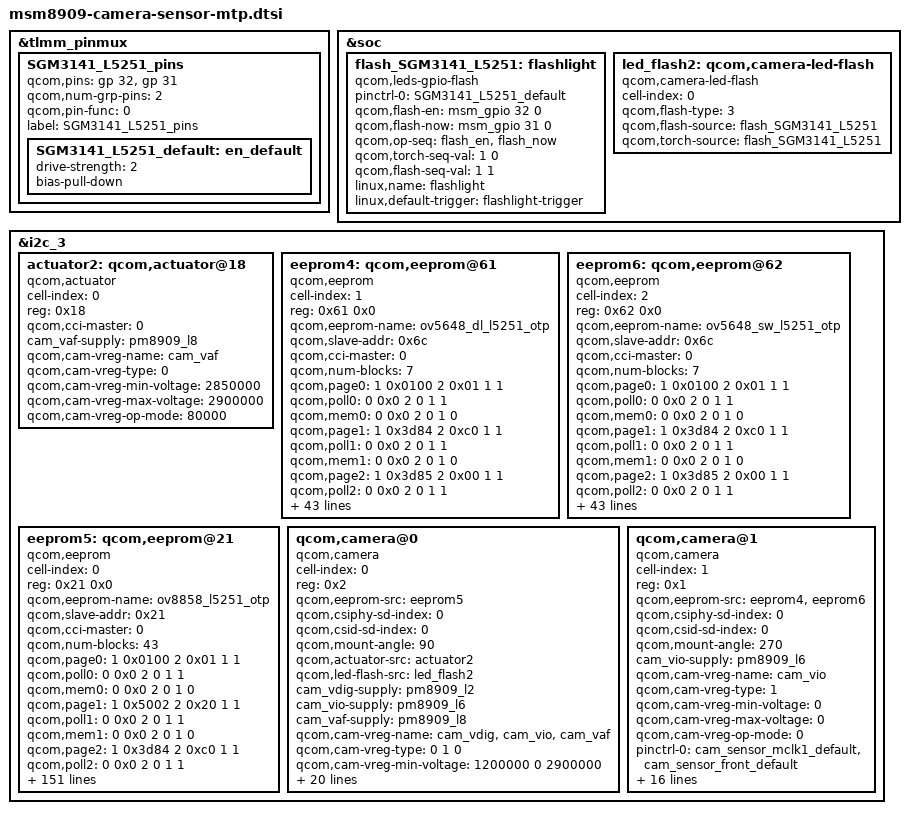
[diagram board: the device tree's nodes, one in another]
/*
 * Copyright (c) 2014-2015, The Linux Foundation. All rights reserved.
 *
 * This program is free software; you can redistribute it and/or modify
 * it under the terms of the GNU General Public License version 2 and
 * only version 2 as published by the Free Software Foundation.
 *
 * This program is distributed in the hope that it will be useful,
 * but WITHOUT ANY WARRANTY; without even the implied warranty of
 * MERCHANTABILITY or FITNESS FOR A PARTICULAR PURPOSE.  See the
 * GNU General Public License for more details.
 */

&tlmm_pinmux {
	SGM3141_L5251_pins {
		qcom,pins = <&gp 32>, <&gp 31>;
		qcom,num-grp-pins = <2>;
		qcom,pin-func = <0>;
		label = "SGM3141_L5251_pins";
		SGM3141_L5251_default: en_default {
		drive-strength = <2>;
		bias-pull-down;
		};
	};
};

&soc {
	flash_SGM3141_L5251:flashlight {
		compatible = "qcom,leds-gpio-flash";
		status = "okay";
		pinctrl-names = "flash_default";
		pinctrl-0 = <&SGM3141_L5251_default>;
		qcom,flash-en = <&msm_gpio 32 0>;
		qcom,flash-now = <&msm_gpio 31 0>;
		qcom,op-seq = "flash_en", "flash_now";
		qcom,torch-seq-val = <1 0>;
		qcom,flash-seq-val = <1 1>;
		linux,name = "flashlight";
		linux,default-trigger = "flashlight-trigger";
	};
	led_flash2: qcom,camera-led-flash {
		cell-index = <0>;
		compatible = "qcom,camera-led-flash";
		qcom,flash-type = <3>;
		qcom,flash-source = <&flash_SGM3141_L5251>;
		qcom,torch-source = <&flash_SGM3141_L5251>;
	};
};

&i2c_3 {

	actuator2: qcom,actuator@18 {
		cell-index = <0>;
		reg = <0x18>;
		compatible = "qcom,actuator";
		qcom,cci-master = <0>;
		cam_vaf-supply = <&pm8909_l8>;
		qcom,cam-vreg-name = "cam_vaf";
		qcom,cam-vreg-type = <0>;
		qcom,cam-vreg-min-voltage = <2850000>;
		qcom,cam-vreg-max-voltage = <2900000>;
		qcom,cam-vreg-op-mode = <80000>;
	};
	// OV5648
        eeprom4: qcom,eeprom@61{
                cell-index = <1>;
                reg = <0x61 0x0>;
                qcom,eeprom-name = "ov5648_dl_l5251_otp";
                compatible = "qcom,eeprom";
                qcom,slave-addr = <0x6c>;
                qcom,cci-master = <0>;
                qcom,num-blocks = <7>;
    
                qcom,page0 = <1 0x0100 2 0x01 1 1>; 
                qcom,poll0 = <0 0x0 2 0 1 1>; 
                qcom,mem0 = <0 0x0 2 0 1 0>; 

                qcom,page1 = <1 0x3d84 2 0xc0 1 1>; 
                qcom,poll1 = <0 0x0 2 0 1 1>; 
                qcom,mem1 = <0 0x0 2 0 1 0>; 
            
                qcom,page2 = <1 0x3d85 2 0x00 1 1>; 
                qcom,poll2 = <0 0x0 2 0 1 1>; 
                qcom,mem2 = <0 0x0 2 0 1 0>; 
            
                qcom,page3 = <1 0x3d86 2 0x0f 1 1>; 
                qcom,pageen3 = <1 0x3d81 2 0x01 1 10>;
                qcom,poll3 = <0 0x0 2 0 1 1>; 
                qcom,mem3 = <16 0x3d00 2 0 1 0>;

                qcom,page4 = <1 0x3d84 2 0xc0 1 1>;
                qcom,poll4 = <0 0x0 2 0 1 1>;
                qcom,mem4 = <0 0x0 2 0 1 0>;
            
                qcom,page5 = <1 0x3d85 2 0x10 1 1>;
                qcom,poll5 = <0 0x0 2 0 1 1>;
                qcom,mem5 = <0 0x0 2 0 1 0>;
            
                qcom,page6 = <1 0x3d86 2 0x1f 1 1>;
                qcom,pageen6 = <1 0x3d81 2 0x01 1 10>;
                qcom,poll6 = <0 0x0 2 0 1 1>;
                qcom,mem6 = <16 0x3d00 2 0 1 0>;

		cam_vio-supply = <&pm8909_l6>;
		qcom,cam-vreg-name = "cam_vio";
		qcom,cam-vreg-type = <1>;
		qcom,cam-vreg-min-voltage = <0>;
		qcom,cam-vreg-max-voltage = <0>;
		qcom,cam-vreg-op-mode = <0>;
		pinctrl-names = "cam_default", "cam_suspend";
		pinctrl-0 = <&cam_sensor_mclk1_default
				&cam_sensor_front_default>;
		pinctrl-1 = <&cam_sensor_mclk1_sleep &cam_sensor_front_sleep>;
		gpios = <&msm_gpio 27 0>,
			<&msm_gpio 28 0>,
			<&msm_gpio 33 0>,
			<&msm_gpio 23 0>;
		qcom,gpio-reset = <1>;
		qcom,gpio-standby = <2>;
		qcom,gpio-vana = <3>;
		qcom,gpio-req-tbl-num = <0 1 2 3>;
		qcom,gpio-req-tbl-flags = <1 0 0 0>;
		qcom,gpio-req-tbl-label = "CAMIF_MCLK",
					"CAM_RESET",
					"CAM_STANDBY",
					"CAM_VANA";
                
		qcom,cam-power-seq-type = "sensor_clk", 
			"sensor_gpio", // Jiangde
			"sensor_gpio",
			"sensor_gpio";
		qcom,cam-power-seq-val = "sensor_cam_mclk", 
			"sensor_gpio_reset", // Jiangde
			"sensor_gpio_standby",
			"sensor_gpio_vana";
		qcom,cam-power-seq-cfg-val = <24000000 1 1 1>;
		qcom,cam-power-seq-delay = <5 10 10 10>;
		clocks = <&clock_gcc clk_mclk1_clk_src>,
				<&clock_gcc clk_gcc_camss_mclk1_clk>;
		clock-names = "cam_src_clk", "cam_clk";
	};
    eeprom6: qcom,eeprom@62{
                cell-index = <2>;
                reg = <0x62 0x0>;
                qcom,eeprom-name = "ov5648_sw_l5251_otp";
                compatible = "qcom,eeprom";
                qcom,slave-addr = <0x6c>;
                qcom,cci-master = <0>;
                qcom,num-blocks = <7>;
    
                qcom,page0 = <1 0x0100 2 0x01 1 1>; 
                qcom,poll0 = <0 0x0 2 0 1 1>; 
                qcom,mem0 = <0 0x0 2 0 1 0>; 

                qcom,page1 = <1 0x3d84 2 0xc0 1 1>; 
                qcom,poll1 = <0 0x0 2 0 1 1>; 
                qcom,mem1 = <0 0x0 2 0 1 0>; 
            
                qcom,page2 = <1 0x3d85 2 0x00 1 1>; 
                qcom,poll2 = <0 0x0 2 0 1 1>; 
                qcom,mem2 = <0 0x0 2 0 1 0>; 
            
                qcom,page3 = <1 0x3d86 2 0x0f 1 1>; 
                qcom,pageen3 = <1 0x3d81 2 0x01 1 10>;
                qcom,poll3 = <0 0x0 2 0 1 1>; 
                qcom,mem3 = <16 0x3d00 2 0 1 0>;

                qcom,page4 = <1 0x3d84 2 0xc0 1 1>;
                qcom,poll4 = <0 0x0 2 0 1 1>;
                qcom,mem4 = <0 0x0 2 0 1 0>;
            
                qcom,page5 = <1 0x3d85 2 0x10 1 1>;
                qcom,poll5 = <0 0x0 2 0 1 1>;
                qcom,mem5 = <0 0x0 2 0 1 0>;
            
                qcom,page6 = <1 0x3d86 2 0x1f 1 1>;
                qcom,pageen6 = <1 0x3d81 2 0x01 1 10>;
                qcom,poll6 = <0 0x0 2 0 1 1>;
                qcom,mem6 = <16 0x3d00 2 0 1 0>;

		cam_vio-supply = <&pm8909_l6>;
		qcom,cam-vreg-name = "cam_vio";
		qcom,cam-vreg-type = <1>;
		qcom,cam-vreg-min-voltage = <0>;
		qcom,cam-vreg-max-voltage = <0>;
		qcom,cam-vreg-op-mode = <0>;
		pinctrl-names = "cam_default", "cam_suspend";
		pinctrl-0 = <&cam_sensor_mclk1_default
				&cam_sensor_front_default>;
		pinctrl-1 = <&cam_sensor_mclk1_sleep &cam_sensor_front_sleep>;
		gpios = <&msm_gpio 27 0>,
			<&msm_gpio 28 0>,
			<&msm_gpio 33 0>,
			<&msm_gpio 23 0>;
		qcom,gpio-reset = <1>;
		qcom,gpio-standby = <2>;
		qcom,gpio-vana = <3>;
		qcom,gpio-req-tbl-num = <0 1 2 3>;
		qcom,gpio-req-tbl-flags = <1 0 0 0>;
		qcom,gpio-req-tbl-label = "CAMIF_MCLK",
					"CAM_RESET",
					"CAM_STANDBY",
					"CAM_VANA";
                
		qcom,cam-power-seq-type = "sensor_clk", 
			"sensor_gpio", // Jiangde
			"sensor_gpio",
			"sensor_gpio";
		qcom,cam-power-seq-val = "sensor_cam_mclk", 
			"sensor_gpio_reset", // Jiangde
			"sensor_gpio_standby",
			"sensor_gpio_vana";
		qcom,cam-power-seq-cfg-val = <24000000 1 1 1>;
		qcom,cam-power-seq-delay = <5 10 10 10>;
		clocks = <&clock_gcc clk_mclk1_clk_src>,
				<&clock_gcc clk_gcc_camss_mclk1_clk>;
		clock-names = "cam_src_clk", "cam_clk";
	};
      //ov8858
      eeprom5: qcom,eeprom@21{
                cell-index = <0>;
                reg = <0x21 0x0>;
                qcom,eeprom-name = "ov8858_l5251_otp";
                compatible = "qcom,eeprom";
                qcom,slave-addr = <0x21>;
                qcom,cci-master = <0>;
                qcom,num-blocks = <43>;
//#####################################################  base info check otp info wb
    		qcom,page0 = <1 0x0100 2 0x01 1 1>;
		qcom,poll0 = <0 0x0 2 0 1 1>;
		qcom,mem0 = <0 0x0 2 0 1 0>;

                qcom,page1 = <1 0x5002 2 0x20 1 1>; 
                qcom,poll1 = <0 0x0 2 0 1 1>; 
                qcom,mem1 = <0 0x0 2 0 1 0>; 

                qcom,page2 = <1 0x3d84 2 0xc0 1 1>; 
                qcom,poll2 = <0 0x0 2 0 1 1>; 
                qcom,mem2 = <0 0x0 2 0 1 0>; 


                qcom,page3 = <1 0x3d88 2 0x70 1 1>; 
                qcom,poll3 = <0 0x0 2 0 1 1>; 
                qcom,mem3 = <0 0x0 2 0 1 0>; 

                qcom,page4 = <1 0x3d89 2 0x10 1 1>; 
                qcom,poll4 = <0 0x0 2 0 1 1>; 
                qcom,mem4 = <0 0x0 2 0 1 0>; 

                qcom,page5 = <1 0x3d8a 2 0x70 1 1>; 
                qcom,poll5 = <0 0x0 2 0 1 1>; 
                qcom,mem5 = <0 0x0 2 0 1 0>; 

                qcom,page6 = <1 0x3d8b 2 0x10 1 1>; 
                qcom,poll6 = <0 0x0 2 0 1 1>; 
                qcom,mem6 = <0 0x0 2 0 1 0>; 

		qcom,page7 = <1 0x3d81 2 0x01 1 10>;
                qcom,poll7 = <0 0x0 2 0 1 1>; 
                qcom,mem7 = <1 0x7010 2 0 1 1>;

//#####################################################  VCM check otp vcm

                qcom,page8 = <1 0x5002 2 0x20 1 1>; 
                qcom,poll8 = <0 0x0 2 0 1 1>; 
                qcom,mem8 = <0 0x0 2 0 1 0>; 

                qcom,page9 = <1 0x3d84 2 0xc0 1 1>; 
                qcom,poll9 = <0 0x0 2 0 1 1>; 
                qcom,mem9 = <0 0x0 2 0 1 0>; 

                qcom,page10 = <1 0x3d88 2 0x70 1 1>; 
                qcom,poll10 = <0 0x0 2 0 1 1>; 
                qcom,mem10 = <0 0x0 2 0 1 0>; 

                qcom,page11 = <1 0x3d89 2 0x21 1 1>; 
                qcom,poll11 = <0 0x0 2 0 1 1>; 
                qcom,mem11 = <0 0x0 2 0 1 0>; 

                qcom,page12 = <1 0x3d8a 2 0x70 1 1>; 
                qcom,poll12 = <0 0x0 2 0 1 1>; 
                qcom,mem12 = <0 0x0 2 0 1 0>; 

		qcom,page13 = <1 0x3d8b 2 0x21 1 1>;
                qcom,poll13 = <0 0x0 2 0 1 1>; 
                qcom,mem13 = <0 0x0 2 0 1 0>; 

		qcom,page14 = <1 0x3d81 2 0x01 1 10>;
                qcom,poll14 = <0 0x0 2 0 1 1>; 
                qcom,mem14 = <1 0x7021 2 0 1 1>;

//#####################################################  lenc check otp lenc


                qcom,page15 = <1 0x5002 2 0x20 1 1>; 
                qcom,poll15 = <0 0x0 2 0 1 1>; 
                qcom,mem15 = <0 0x0 2 0 1 0>; 

		qcom,page16 = <1 0x3d84 2 0xc0 1 1>;
                qcom,poll16 = <0 0x0 2 0 1 1>; 
                qcom,mem16 = <0 0x0 2 0 1 0>;

		qcom,page17 = <1 0x3d88 2 0x70 1 1>;
                qcom,poll17 = <0 0x0 2 0 1 1>; 
                qcom,mem17 = <0 0x0 2 0 1 0>;

		qcom,page18 = <1 0x3d89 2 0x28 1 1>;
                qcom,poll18 = <0 0x0 2 0 1 1>; 
                qcom,mem18 = <0 0x0 2 0 1 0>;

		qcom,page19 = <1 0x3d8a 2 0x70 1 1>;
                qcom,poll19 = <0 0x0 2 0 1 1>; 
                qcom,mem19 = <0 0x0 2 0 1 0>;

		qcom,page20 = <1 0x3d8b 2 0x28 1 1>;
                qcom,poll20 = <0 0x0 2 0 1 1>; 
                qcom,mem20 = <0 0x0 2 0 1 0>;

		qcom,page21 = <1 0x3d81 2 0x01 1 10>;
                qcom,poll21 = <0 0x0 2 0 1 1>; 
                qcom,mem21 = <1 0x7028 2 0 1 1>;

//#####################################################  wb read otp wb

                qcom,page22 = <1 0x5002 2 0x20 1 1>; 
                qcom,poll22 = <0 0x0 2 0 1 1>; 
                qcom,mem22 = <0 0x0 2 0 1 0>; 

		qcom,page23 = <1 0x3d84 2 0xc0 1 2>;
		qcom,poll23 = <0 0x0 2 0 1 1>; 
                qcom,mem23 = <0 0x0 2 0 1 0>;

		qcom,page24 = <1 0x3d88 2 0x70 1 2>;
		qcom,poll24 = <0 0x0 2 0 1 1>; 
                qcom,mem24 = <0 0x0 2 0 1 0>;

		qcom,page25 = <1 0x3d89 2 0x11 1 2>;
		qcom,poll25 = <0 0x0 2 0 1 1>; 
                qcom,mem25 = <0 0x0 2 0 1 0>;

		qcom,page26 = <1 0x3d8a 2 0x70 1 2>;
		qcom,poll26 = <0 0x0 2 0 1 1>; 
                qcom,mem26 = <0 0x0 2 0 1 0>;

		qcom,page27 = <1 0x3d8b 2 0x20 1 2>;
		qcom,poll27 = <0 0x0 2 0 1 1>; 
                qcom,mem27 = <0 0x0 2 0 1 0>;

		qcom,page28 = <1 0x3d81 2 0x01 1 5>;
		qcom,poll28 = <0 0x0 2 0 1 1>; 
                qcom,mem28 = <16 0x7011 2 0 1 0>;

//#####################################################  wb read vcm 

                qcom,page29 = <1 0x5002 2 0x20 1 1>; 
                qcom,poll29 = <0 0x0 2 0 1 1>; 
                qcom,mem29 = <0 0x0 2 0 1 0>; 


		qcom,page30 = <1 0x3d84 2 0xc0 1 2>;
		qcom,poll30 = <0 0x0 2 0 1 1>; 
                qcom,mem30 = <0 0x0 2 0 1 0>;

		qcom,page31 = <1 0x3d88 2 0x70 1 2>;
		qcom,poll31 = <0 0x0 2 0 1 1>; 
                qcom,mem31 = <0 0x0 2 0 1 0>;

		qcom,page32 = <1 0x3d89 2 0x22 1 2>;
		qcom,poll32 = <0 0x0 2 0 1 1>; 
                qcom,mem32 = <0 0x0 2 0 1 0>;

		qcom,page33 = <1 0x3d8a 2 0x70 1 2>;
		qcom,poll33 = <0 0x0 2 0 1 1>; 
                qcom,mem33 = <0 0x0 2 0 1 0>;

		qcom,page34 = <1 0x3d8b 2 0x27 1 2>;
		qcom,poll34 = <0 0x0 2 0 1 1>; 
                qcom,mem34 = <0 0x0 2 0 1 0>;

		qcom,page35 = <1 0x3d81 2 0x01 1 5>;
		qcom,poll35 = <0 0x0 2 0 1 1>; 
                qcom,mem35 = <6 0x7022 2 0 1 0>;

//#####################################################  wb read lenc 

                qcom,page36 = <1 0x5002 2 0x20 1 1>; 
                qcom,poll36 = <0 0x0 2 0 1 1>; 
                qcom,mem36 = <0 0x0 2 0 1 0>; 


		qcom,page37 = <1 0x3d84 2 0xc0 1 2>;
		qcom,poll37 = <0 0x0 2 0 1 1>; 
                qcom,mem37 = <0 0x0 2 0 1 0>;

		qcom,page38 = <1 0x3d88 2 0x70 1 2>;
		qcom,poll38 = <0 0x0 2 0 1 1>; 
                qcom,mem38 = <0 0x0 2 0 1 0>;

		qcom,page39 = <1 0x3d89 2 0x29 1 2>;
		qcom,poll39 = <0 0x0 2 0 1 1>; 
                qcom,mem39 = <0 0x0 2 0 1 0>;

		qcom,page40 = <1 0x3d8a 2 0x72 1 2>;
		qcom,poll40 = <0 0x0 2 0 1 1>; 
                qcom,mem40 = <0 0x0 2 0 1 0>;

		qcom,page41 = <1 0x3d8b 2 0x09 1 2>;
		qcom,poll41 = <0 0x0 2 0 1 1>; 
                qcom,mem41 = <0 0x0 2 0 1 0>;

		qcom,page42 = <1 0x3d81 2 0x01 1 5>;
		qcom,poll42 = <0 0x0 2 0 1 1>; 
                qcom,mem42 = <480 0x7029 2 0 1 0>;

		cam_vdig-supply = <&pm8909_l2>;
		cam_vio-supply = <&pm8909_l6>;
		cam_vaf-supply = <&pm8909_l8>;
		qcom,cam-vreg-name = "cam_vdig", "cam_vio","cam_vaf";
		qcom,cam-vreg-type = <0 1 0>;
		qcom,cam-vreg-min-voltage = <1200000 0 2850000>;
		qcom,cam-vreg-max-voltage = <1200000 0 2900000>;
		qcom,cam-vreg-op-mode = <200000 0 100000>;
		pinctrl-names = "cam_default", "cam_suspend";
		pinctrl-0 = <&cam_sensor_mclk0_default
				&cam_sensor_rear_default>;
		pinctrl-1 = <&cam_sensor_mclk0_sleep &cam_sensor_rear_sleep>;
		gpios = <&msm_gpio 26 0>,
			<&msm_gpio 35 0>,
			<&msm_gpio 34 0>,
			<&msm_gpio 23 0>;
		qcom,gpio-reset = <1>;
		qcom,gpio-standby = <2>;
		qcom,gpio-vana = <3>;
		qcom,gpio-req-tbl-num = <0 1 2 3>;
		qcom,gpio-req-tbl-flags = <1 0 0 0>;
		qcom,gpio-req-tbl-label = "CAMIF_MCLK",
			"CAM_RESET1",
			"CAM_STANDBY",
			"CAM_VANA";
		qcom,cam-power-seq-type = "sensor_clk", 
			"sensor_gpio", // Jiangde
			"sensor_gpio",
			"sensor_gpio";
		qcom,cam-power-seq-val = "sensor_cam_mclk", 
			"sensor_gpio_reset", // Jiangde
			"sensor_gpio_vana",
			"sensor_gpio_standby";
		qcom,cam-power-seq-cfg-val = <24000000 1 1 1>;
		qcom,cam-power-seq-delay = <5 10 10 10>;
		clocks = <&clock_gcc clk_mclk0_clk_src>,
				<&clock_gcc clk_gcc_camss_mclk0_clk>;
		clock-names = "cam_src_clk", "cam_clk";
	};
	qcom,camera@0 {
		cell-index = <0>;
		compatible = "qcom,camera";
		reg = <0x2>;
		qcom,eeprom-src = <&eeprom5>;
		qcom,csiphy-sd-index = <0>;
		qcom,csid-sd-index = <0>;
		qcom,mount-angle = <90>;
		qcom,actuator-src = <&actuator2>;
		qcom,led-flash-src = <&led_flash2>;
		cam_vdig-supply = <&pm8909_l2>;
		cam_vio-supply = <&pm8909_l6>;
		cam_vaf-supply = <&pm8909_l8>;
		qcom,cam-vreg-name = "cam_vdig", "cam_vio","cam_vaf";
		qcom,cam-vreg-type = <0 1 0>;
		qcom,cam-vreg-min-voltage = <1200000 0 2900000>;
		qcom,cam-vreg-max-voltage = <1200000 0 2900000>;
		qcom,cam-vreg-op-mode = <200000 0 80000>;
		pinctrl-names = "cam_default", "cam_suspend";
		pinctrl-0 = <&cam_sensor_mclk0_default
				&cam_sensor_rear_default>;
		pinctrl-1 = <&cam_sensor_mclk0_sleep &cam_sensor_rear_sleep>;
		gpios = <&msm_gpio 26 0>,
			<&msm_gpio 35 0>,
			<&msm_gpio 34 0>,
			<&msm_gpio 23 0>;
		qcom,gpio-reset = <1>;
		qcom,gpio-standby = <2>;
		qcom,gpio-vana = <3>;
		qcom,gpio-req-tbl-num = <0 1 2 3>;
		qcom,gpio-req-tbl-flags = <1 0 0 0>;
		qcom,gpio-req-tbl-label = "CAMIF_MCLK",
			"CAM_RESET1",
			"CAM_STANDBY",
			"CAM_VANA";
		qcom,sensor-position = <0>;
		qcom,sensor-mode = <0>;
		qcom,cci-master = <0>;
		status = "ok";
		clocks = <&clock_gcc clk_mclk0_clk_src>,
				<&clock_gcc clk_gcc_camss_mclk0_clk>;
		clock-names = "cam_src_clk", "cam_clk";
	};

	qcom,camera@1 {
		cell-index = <1>;
		compatible = "qcom,camera";
		reg = <0x1>;
		qcom,eeprom-src = <&eeprom4 &eeprom6>;
		qcom,csiphy-sd-index = <0>;
		qcom,csid-sd-index = <0>;
		qcom,mount-angle = <270>;
		cam_vio-supply = <&pm8909_l6>;
		qcom,cam-vreg-name = "cam_vio";
		qcom,cam-vreg-type = <1>;
		qcom,cam-vreg-min-voltage = <0>;
		qcom,cam-vreg-max-voltage = <0>;
		qcom,cam-vreg-op-mode = <0>;
		pinctrl-names = "cam_default", "cam_suspend";
		pinctrl-0 = <&cam_sensor_mclk1_default
				&cam_sensor_front_default>;
		pinctrl-1 = <&cam_sensor_mclk1_sleep &cam_sensor_front_sleep>;
		gpios = <&msm_gpio 27 0>,
			<&msm_gpio 28 0>,
			<&msm_gpio 33 0>,
			<&msm_gpio 23 0>;
		qcom,gpio-reset = <1>;
		qcom,gpio-standby = <2>;
		qcom,gpio-vana = <3>;
		qcom,gpio-req-tbl-num = <0 1 2 3>;
		qcom,gpio-req-tbl-flags = <1 0 0 0>;
		qcom,gpio-req-tbl-label = "CAMIF_MCLK",
					"CAM_RESET",
					"CAM_STANDBY",
					"CAM_VANA";
		qcom,sensor-position = <1>;
		qcom,sensor-mode = <0>;
		qcom,cci-master = <0>;
		status = "ok";
		clocks = <&clock_gcc clk_mclk1_clk_src>,
				<&clock_gcc clk_gcc_camss_mclk1_clk>;
		clock-names = "cam_src_clk", "cam_clk";
	};
};
